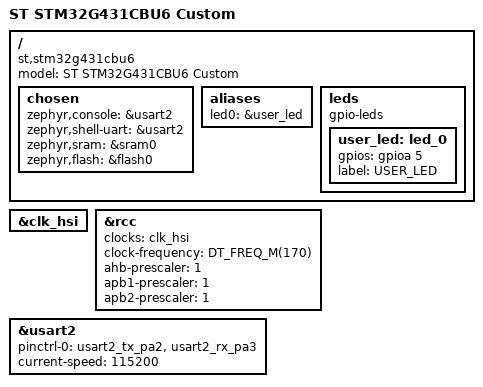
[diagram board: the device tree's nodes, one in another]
/dts-v1/;
#include <st/g4/stm32g431Xb.dtsi>
#include <st/g4/stm32g431c(6-8-b)ux-pinctrl.dtsi>

/ {
	model = "ST STM32G431CBU6 Custom";
	compatible = "st,stm32g431cbu6";

	chosen {
		zephyr,console = &usart2;
		zephyr,shell-uart = &usart2;
		zephyr,sram = &sram0;
		zephyr,flash = &flash0;
	};

	aliases {
		led0 = &user_led;
	};

	leds {
		compatible = "gpio-leds";
		user_led: led_0 {
			gpios = <&gpioa 5 GPIO_ACTIVE_HIGH>;
			label = "USER_LED";
		};
	};
};

&clk_hsi {
	status = "okay";
};

&rcc {
	clocks = <&clk_hsi>;
	clock-frequency = <DT_FREQ_M(170)>;
	ahb-prescaler = <1>;
	apb1-prescaler = <1>;
	apb2-prescaler = <1>;
};

&usart2 {
	pinctrl-0 = <&usart2_tx_pa2 &usart2_rx_pa3>;
	pinctrl-names = "default";
	current-speed = <115200>;
	status = "okay";
};
